# f28004x_eqep_regs register map
Vendor: Texas Instruments
Peripheral module from a debugger description file (folder C2000).
Address unit: 16 bits
Registers are 16-bit, read-write, no defined reset value unless marked. A register's access mark holds for its fields unless they carry their own. Offsets are as the file gives them; lines under a group give offsets from that group; [hi:lo] are bit positions; {n}, {i} and the like mark numbered series; 'fields as' and 'values as' point back to an identical list; <NAME> marks a mode.

## EQEP_REGS — EQEP Registers
0x00 QPOSCNT 32-bit — Position Counter
0x02 QPOSINIT 32-bit — Position Counter Init
0x04 QPOSMAX 32-bit — Maximum Position Count
0x06 QPOSCMP 32-bit — Position Compare
0x08 QPOSILAT 32-bit ro — Index Position Latch
0x0A QPOSSLAT 32-bit ro — Strobe Position Latch
0x0C QPOSLAT 32-bit ro — Position Latch
0x0E QUTMR 32-bit — QEP Unit Timer
0x10 QUPRD 32-bit — QEP Unit Period
0x12 QWDTMR — QEP Watchdog Timer
0x13 QWDPRD — QEP Watchdog Period
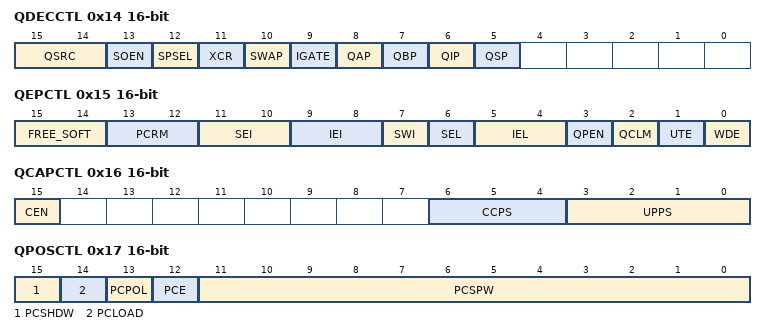
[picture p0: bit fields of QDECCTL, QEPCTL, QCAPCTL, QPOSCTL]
0x14 QDECCTL — Quadrature Decoder Control
  [15:14] QSRC — Position-counter source selection
  [13] SOEN — Sync output-enable
  [12] SPSEL — Sync output pin selection
  [11] XCR — External Clock Rate
  [10] SWAP — CLK/DIR Signal Source for Position Counter
  [9] IGATE — Index pulse gating option
  [8] QAP — QEPA input polarity
  [7] QBP — QEPB input polarity
  [6] QIP — QEPI input polarity
  [5] QSP — QEPS input polarity
0x15 QEPCTL — QEP Control
  [15:14] FREE_SOFT — Emulation mode
  [13:12] PCRM — Postion counter reset
  [11:10] SEI — Strobe event init
  [9:8] IEI — Index event init of position count
  [7] SWI — Software init position counter
  [6] SEL — Strobe event latch
  [5:4] IEL — Index event latch
  [3] QPEN — Quadrature postotion counter enable
  [2] QCLM — QEP capture latch mode
  [1] UTE — QEP unit timer enable
  [0] WDE — QEP watchdog enable
0x16 QCAPCTL — Qaudrature Capture Control
  [15] CEN — Enable eQEP capture
  [6:4] CCPS — eQEP capture timer clock prescaler
  [3:0] UPPS — Unit position event prescaler
0x17 QPOSCTL — Position Compare Control
  [15] PCSHDW — Position compare of shadow enable
  [14] PCLOAD — Position compare of shadow load
  [13] PCPOL — Polarity of sync output
  [12] PCE — Position compare enable/disable
  [11:0] PCSPW — Position compare sync pulse width
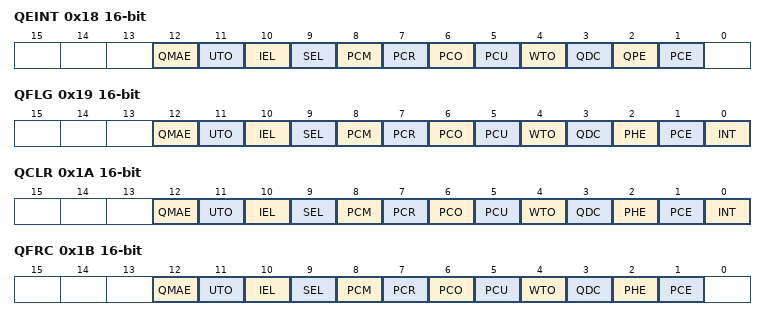
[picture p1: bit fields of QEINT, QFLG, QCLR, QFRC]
0x18 QEINT — QEP Interrupt Control
  [12] QMAE — QMA error interrupt enable
  [11] UTO — Unit time out interrupt enable
  [10] IEL — Index event latch interrupt enable
  [9] SEL — Strobe event latch interrupt enable
  [8] PCM — Position-compare match interrupt enable
  [7] PCR — Position-compare ready interrupt enable
  [6] PCO — Position counter overflow interrupt enable
  [5] PCU — Position counter underflow interrupt enable
  [4] WTO — Watchdog time out interrupt enable
  [3] QDC — Quadrature direction change interrupt enable
  [2] QPE — Quadrature phase error interrupt enable
  [1] PCE — Position counter error interrupt enable
0x19 QFLG ro — QEP Interrupt Flag
  [12] QMAE — QMA error interrupt flag
  [11] UTO — Unit time out interrupt flag
  [10] IEL — Index event latch interrupt flag
  [9] SEL — Strobe event latch interrupt flag
  [8] PCM — eQEP compare match event interrupt flag
  [7] PCR — Position-compare ready interrupt flag
  [6] PCO — Position counter overflow interrupt flag
  [5] PCU — Position counter underflow interrupt flag
  [4] WTO — Watchdog timeout interrupt flag
  [3] QDC — Quadrature direction change interrupt flag
  [2] PHE — Quadrature phase error interrupt flag
  [1] PCE — Position counter error interrupt flag
  [0] INT — Global interrupt status flag
0x1A QCLR access not given — QEP Interrupt Clear
  [12] QMAE — Clear QMA error interrupt flag (access R=0/W=1)
  [11] UTO — Clear unit time out interrupt flag (access R=0/W=1)
  [10] IEL — Clear index event latch interrupt flag (access R=0/W=1)
  [9] SEL — Clear strobe event latch interrupt flag (access R=0/W=1)
  [8] PCM — Clear eQEP compare match event interrupt flag (access R=0/W=1)
  [7] PCR — Clear position-compare ready interrupt flag (access R=0/W=1)
  [6] PCO — Clear position counter overflow interrupt flag (access R=0/W=1)
  [5] PCU — Clear position counter underflow interrupt flag (access R=0/W=1)
  [4] WTO — Clear watchdog timeout interrupt flag (access R=0/W=1)
  [3] QDC — Clear quadrature direction change interrupt flag (access R=0/W=1)
  [2] PHE — Clear quadrature phase error interrupt flag (access R=0/W=1)
  [1] PCE — Clear position counter error interrupt flag (access R=0/W=1)
  [0] INT — Global interrupt clear flag (access R=0/W=1)
0x1B QFRC — QEP Interrupt Force
  [12] QMAE — Force QMA error interrupt
  [11] UTO — Force unit time out interrupt
  [10] IEL — Force index event latch interrupt
  [9] SEL — Force strobe event latch interrupt
  [8] PCM — Force position-compare match interrupt
  [7] PCR — Force position-compare ready interrupt
  [6] PCO — Force position counter overflow interrupt
  [5] PCU — Force position counter underflow interrupt
  [4] WTO — Force watchdog time out interrupt
  [3] QDC — Force quadrature direction change interrupt
  [2] PHE — Force quadrature phase error interrupt
  [1] PCE — Force position counter error interrupt
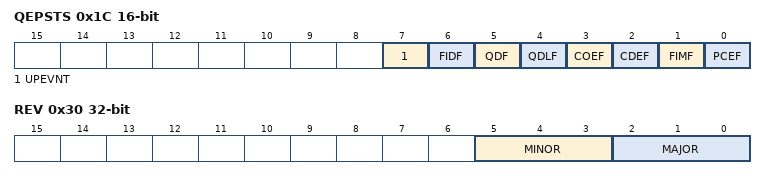
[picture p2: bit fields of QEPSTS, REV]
0x1C QEPSTS access not given — QEP Status
  [7] UPEVNT — Unit position event flag (access R/W=1)
  [6] FIDF ro — The first index marker
  [5] QDF ro — Quadrature direction flag
  [4] QDLF ro — eQEP direction latch flag
  [3] COEF — Capture overflow error flag (access R/W=1)
  [2] CDEF — Capture direction error flag (access R/W=1)
  [1] FIMF — First index marker flag (access R/W=1)
  [0] PCEF ro — Position counter error flag.
0x1D QCTMR — QEP Capture Timer
  [15:0] QCTMR — This register provides time base for edge capture unit.
0x1E QCPRD — QEP Capture Period
  [15:0] QCPRD — Period count value between eQEP position events
0x1F QCTMRLAT ro — QEP Capture Latch
  [15:0] QCTMRLAT — The eQEP capture timer latch value
0x20 QCPRDLAT ro — QEP Capture Period Latch
  [15:0] QCPRDLAT — eQEP capture period latch value
0x30 REV 32-bit ro — QEP Revision Number
  [5:3] MINOR — Minor Revision Number
  [2:0] MAJOR — Major Revision Number
0x32 QEPSTROBESEL 32-bit — QEP Strobe select register
  [1:0] STROBESEL — QMA Mode Select
0x34 QMACTRL 32-bit — QMA Control register
  [2:0] MODE — QMA Mode Select
